# DDR32SS0_CTLPHY_WRAP_CTL_CFG_CTLCFG register map
Vendor: Texas Instruments
Registers are 32-bit, read-write, reset 0x0 unless marked. A register's access mark holds for its fields unless they carry their own. Offsets are as the file gives them; [hi:lo] are bit positions; lines under a group give offsets from that group; {n}, {i} and the like mark numbered series.

## DDR32SS0_CTLPHY_WRAP_CTL_CFG_CTLCFG (part 4 of 11)
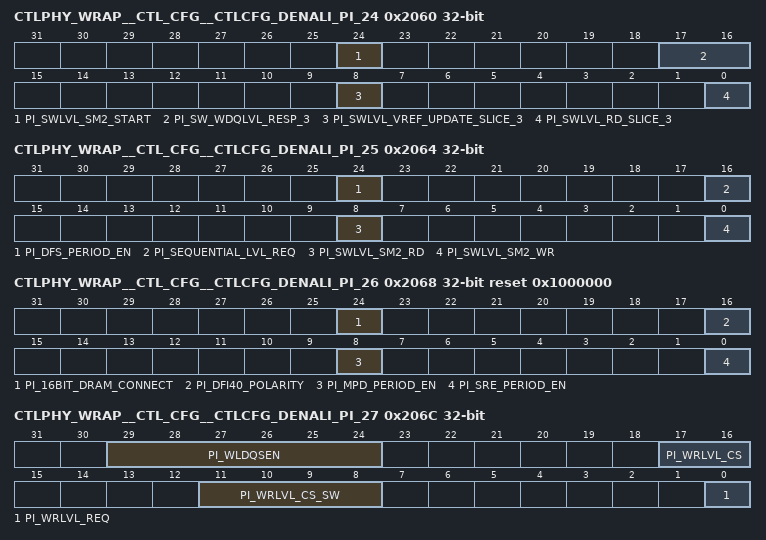
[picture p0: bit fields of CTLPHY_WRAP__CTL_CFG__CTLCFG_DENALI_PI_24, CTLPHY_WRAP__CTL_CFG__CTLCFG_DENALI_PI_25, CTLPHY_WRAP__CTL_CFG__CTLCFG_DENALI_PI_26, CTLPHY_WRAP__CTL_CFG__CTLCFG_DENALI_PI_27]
0x2060 CTLPHY_WRAP__CTL_CFG__CTLCFG_DENALI_PI_24 access per field
  [24] PI_SWLVL_SM2_START wo — SW leveling start command for stage 2. WRITE-ONLY
  [17:16] PI_SW_WDQLVL_RESP_3 ro — Leveling response for data slice 3. READ-ONLY
  [8] PI_SWLVL_VREF_UPDATE_SLICE_3 wo — SW leveling vref update command in WDQ training. WRITE-ONLY
  [0] PI_SWLVL_RD_SLICE_3 wo — SW leveling read command in WDQ training. WRITE-ONLY
0x2064 CTLPHY_WRAP__CTL_CFG__CTLCFG_DENALI_PI_25 access per field
  [24] PI_DFS_PERIOD_EN rw — Enable the DFS triggered periodic leveling.
  [16] PI_SEQUENTIAL_LVL_REQ wo — User request to initiate all possible leveling sequences. Set to 1 to trigger. WRITE-ONLY
  [8] PI_SWLVL_SM2_RD wo — SW leveling read command for stage 2. WRITE-ONLY
  [0] PI_SWLVL_SM2_WR wo — SW leveling write command for stage 2. WRITE-ONLY
0x2068 CTLPHY_WRAP__CTL_CFG__CTLCFG_DENALI_PI_26 reset 0x1000000
  [24] PI_16BIT_DRAM_CONNECT — Enable 16/32 bit DRAM configuration. 0: 16bit DRAM. 1: 32 bit DRAM.
  [16] PI_DFI40_POLARITY — Defines the polarity of the dfi_wrdata_cs_n/dfi_rddata_cs_n signals.
  [8] PI_MPD_PERIOD_EN — Enable the max power saving mode exit triggered periodic leveling.
  [0] PI_SRE_PERIOD_EN — Enable the self refresh exit triggered periodic leveling.
0x206C CTLPHY_WRAP__CTL_CFG__CTLCFG_DENALI_PI_27 access per field
  [29:24] PI_WLDQSEN rw — Delay from issuing MRS to first DQS strobe for write leveling.
  [17:16] PI_WRLVL_CS rw — Specifies the target chip select for the write leveling operation initiated through the WRLVL_REQ parameter.
  [11:8] PI_WRLVL_CS_SW rw — Specifies the target chip select for the write leveling operation initiated through the WRLVL_REQ parameter.
  [0] PI_WRLVL_REQ wo — User request to initiate write leveling. Set to 1 to trigger. WRITE-ONLY
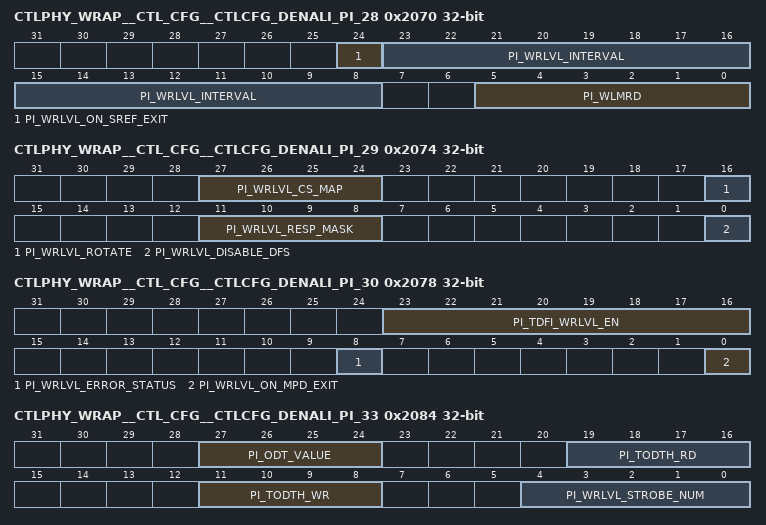
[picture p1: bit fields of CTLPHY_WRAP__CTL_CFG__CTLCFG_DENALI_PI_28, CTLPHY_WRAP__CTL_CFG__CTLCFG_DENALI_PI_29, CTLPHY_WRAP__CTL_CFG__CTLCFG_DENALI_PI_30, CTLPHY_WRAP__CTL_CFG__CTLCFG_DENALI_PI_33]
0x2070 CTLPHY_WRAP__CTL_CFG__CTLCFG_DENALI_PI_28
  [24] PI_WRLVL_ON_SREF_EXIT — Enables automatic write leveling on a self-refresh exit. Set to 1 to enable.
  [23:8] PI_WRLVL_INTERVAL — Number of long count sequences counted between automatic write leveling commands.
  [5:0] PI_WLMRD — Delay from issuing MRS to first write leveling strobe.
0x2074 CTLPHY_WRAP__CTL_CFG__CTLCFG_DENALI_PI_29
  [27:24] PI_WRLVL_CS_MAP — Defines the chip select map for write leveling operations. Bit [0] controls cs0, bit [1] controls cs1, etc. Set each bit to 1 to enable chip for write leveling.
  [16] PI_WRLVL_ROTATE — Enables rotational CS for counter triggered automatic write leveling. Set to 1, only one rank's write levling will process, the rank number is rotational for each time that write leveling been triggered by counter expiring. Set to 0 or not a short pattern leveling [indicated by dfi_lvl_periodic], the counter expired write leveling will process all the ranks.
  [11:8] PI_WRLVL_RESP_MASK — Mask for the dfi_wrlvl_resp signal during write leveling.
  [0] PI_WRLVL_DISABLE_DFS — Disable automatic write leveling on freq change. Set to 1 to disable wrlvl on dfs,set 0 enable wrlvl on dfs.
0x2078 CTLPHY_WRAP__CTL_CFG__CTLCFG_DENALI_PI_30 access per field
  [23:16] PI_TDFI_WRLVL_EN rw — Defines the DFI tWRLVL_EN timing parameter [in DFI clocks], the minimum cycles from a dfi_wrlvl_en assertion to the first dfi_wrlvl_strobe assertion.
  [8] PI_WRLVL_ERROR_STATUS ro — Holds the error associated with the write level error interrupt. Bit [0] set indicates a TDFI_WRLVL_MAX parameter violation and bit [1] set indicates a TDFI_WRLVL_RESP parameter violation. READ-ONLY
  [0] PI_WRLVL_ON_MPD_EXIT rw — Enables automatic write leveling on a maximum power down mode exit. Set to 1 to enable.
0x207C CTLPHY_WRAP__CTL_CFG__CTLCFG_DENALI_PI_31
  [31:0] PI_TDFI_WRLVL_RESP — Defines the DFI tWRLVL_RESP timing parameter [in DFI clocks], the maximum cycles between a dfi_wrlvl_req assertion and a dfi_wrlvl_en assertion.
0x2080 CTLPHY_WRAP__CTL_CFG__CTLCFG_DENALI_PI_32
  [31:0] PI_TDFI_WRLVL_MAX — Defines the DFI tWRLVL_MAX timing parameter [in DFI clocks], the maximum cycles between a dfi_wrlvl_en assertion and a valid dfi_wrlvl_resp.
0x2084 CTLPHY_WRAP__CTL_CFG__CTLCFG_DENALI_PI_33
  [27:24] PI_ODT_VALUE — When using LPDDR4, this value will be driven out on the dfi_odt signal.
  [19:16] PI_TODTH_RD — Defines the minimum DRAM cycles of ODT high time for a read command, in memory clocks.
  [11:8] PI_TODTH_WR — Defines the minimum DRAM cycles of ODT high time for a write command, in memory clocks.
  [4:0] PI_WRLVL_STROBE_NUM — Defines the number of write leveling strobes generated.
0x2088 CTLPHY_WRAP__CTL_CFG__CTLCFG_DENALI_PI_34
  [3:0] PI_ADDRESS_MIRRORING — Indicates which chip selects support address mirroring. Bit [0] controls cs0, bit [1] controls cs1, etc. Set each bit to 1 to enable.
0x208C CTLPHY_WRAP__CTL_CFG__CTLCFG_DENALI_PI_35
  [25:0] PI_CA_PARITY_ERROR_INJECT — Selects bit to corrupt on the CA bus for CA parity error injection.
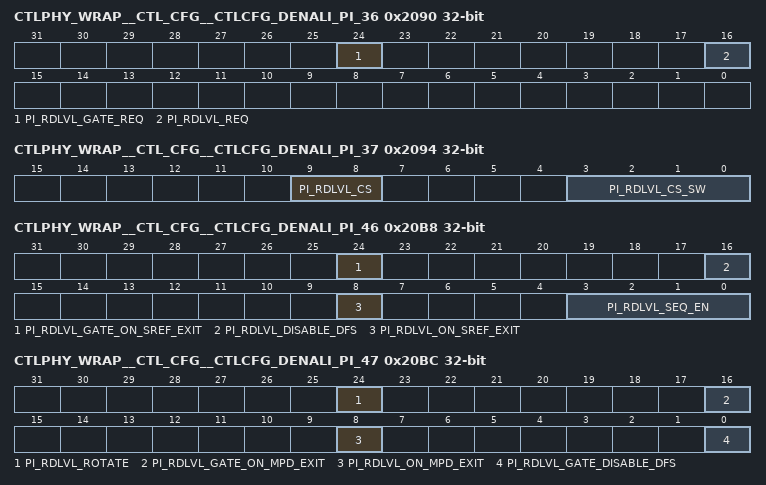
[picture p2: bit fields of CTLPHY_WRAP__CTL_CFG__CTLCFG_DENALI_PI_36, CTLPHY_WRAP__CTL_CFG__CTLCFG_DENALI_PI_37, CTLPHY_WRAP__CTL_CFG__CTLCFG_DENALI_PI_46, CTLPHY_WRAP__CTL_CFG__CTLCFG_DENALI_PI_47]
0x2090 CTLPHY_WRAP__CTL_CFG__CTLCFG_DENALI_PI_36 wo
  [24] PI_RDLVL_GATE_REQ — User request to initiate gate training. Set to 1 to trigger. WRITE-ONLY
  [16] PI_RDLVL_REQ — User request to initiate data eye training. Set to 1 to trigger. WRITE-ONLY
0x2094 CTLPHY_WRAP__CTL_CFG__CTLCFG_DENALI_PI_37
  [9:8] PI_RDLVL_CS — Specifies the target chip select for the data eye training operation initiated through the RDLVL_REQ parameter or the gate training operation initiated through the RDLVL_GATE_REQ parameter.
  [3:0] PI_RDLVL_CS_SW — Specifies the target chip select for the data eye training operation initiated through the RDLVL_REQ parameter or the gate training operation initiated through the RDLVL_GATE_REQ parameter.
{0x2000+4i} CTLPHY_WRAP__CTL_CFG__CTLCFG_DENALI_PI_{i} (i=38..45)
  [31:0] PI_RDLVL_PAT_{i-38} — Non-default pattern {i-38} used for read data eye training of DDR4 or LPDDR4, and read dbi training of DDR4.
0x20B8 CTLPHY_WRAP__CTL_CFG__CTLCFG_DENALI_PI_46
  [24] PI_RDLVL_GATE_ON_SREF_EXIT — Enables automatic gate training on a self-refresh exit. Set to 1 to enable.
  [16] PI_RDLVL_DISABLE_DFS — Disables automatic data eye training on freq change. Set to 1 to disable rdlvl on dfs,Set to 0 to enable rdlvl on dfs.
  [8] PI_RDLVL_ON_SREF_EXIT — Enables automatic data eye training on a self-refresh exit. Set to 1 to enable.
  [3:0] PI_RDLVL_SEQ_EN — Specifies the pattern, format and MPR for data eye training.
0x20BC CTLPHY_WRAP__CTL_CFG__CTLCFG_DENALI_PI_47
  [24] PI_RDLVL_ROTATE — Enables rotational CS for interval data eye training. Set to 1 for rotating CS.
  [16] PI_RDLVL_GATE_ON_MPD_EXIT — Enables automatic gate training on a maximum power down mode exit. Set to 1 to enable.
  [8] PI_RDLVL_ON_MPD_EXIT — Enables automatic data eye training on a maximum power down mode exit. Set to 1 to enable.
  [0] PI_RDLVL_GATE_DISABLE_DFS — Disables automatic gate training on freq change. Set to 1 to disable rdlvl_gate on dfs,Set to 0 to enable rdlvl_gate on dfs.
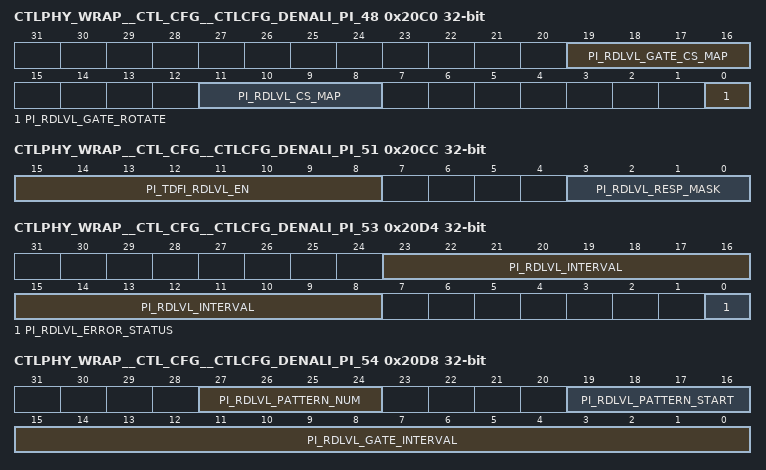
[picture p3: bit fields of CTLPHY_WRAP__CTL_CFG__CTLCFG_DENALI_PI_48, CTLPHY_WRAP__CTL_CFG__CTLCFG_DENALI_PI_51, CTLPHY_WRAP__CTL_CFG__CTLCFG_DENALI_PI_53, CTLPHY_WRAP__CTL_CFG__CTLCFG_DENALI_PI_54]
0x20C0 CTLPHY_WRAP__CTL_CFG__CTLCFG_DENALI_PI_48
  [19:16] PI_RDLVL_GATE_CS_MAP — Defines the chip select map for gate training operations. Bit [0] controls cs0, bit [1] controls cs1, etc. Set each bit to 1 to enable chip for gate training.
  [11:8] PI_RDLVL_CS_MAP — Defines the chip select map for data eye training operations. Bit [0] controls cs0, bit [1] controls cs1, etc. Set each bit to 1 to enable chip for data eye training.
  [0] PI_RDLVL_GATE_ROTATE — Enables rotational CS for interval gate training. Set to 1 for rotating CS.
0x20C4 CTLPHY_WRAP__CTL_CFG__CTLCFG_DENALI_PI_49
  [9:0] PI_TDFI_RDLVL_RR — Defines the DFI tRDLVL_RR timing parameter [in DFI clocks], the minimum cycles between read commands.
0x20C8 CTLPHY_WRAP__CTL_CFG__CTLCFG_DENALI_PI_50
  [31:0] PI_TDFI_RDLVL_RESP — Defines the DFI tRDLVL_RESP timing parameter [in DFI clocks], the maximum cycles between a dfi_rdlvl_req or dfi_rdlvl_gate_req assertion and a dfi_rdlvl_en or dfi_rdlvl_gate_en assertion.
0x20CC CTLPHY_WRAP__CTL_CFG__CTLCFG_DENALI_PI_51
  [15:8] PI_TDFI_RDLVL_EN — Defines the DFI tRDLVL_EN timing parameter [in DFI clocks], the minimum cycles from a dfi_rdlvl_en or dfi_rdlvl_gate_en assertion to the first read or MRR. Set to 1 means the minium value[1 cycle], set to 0 means the maxium value
  [3:0] PI_RDLVL_RESP_MASK — Mask for the dfi_rdlvl_resp signal during data eye training.
0x20D0 CTLPHY_WRAP__CTL_CFG__CTLCFG_DENALI_PI_52
  [31:0] PI_TDFI_RDLVL_MAX — Defines the DFI tRDLVL_MAX timing parameter [in DFI clocks], the maximum cycles between a dfi_rdlvl_en or dfi_rdlvl_gate_en assertion and a valid dfi_rdlvl_resp.
0x20D4 CTLPHY_WRAP__CTL_CFG__CTLCFG_DENALI_PI_53 access per field
  [23:8] PI_RDLVL_INTERVAL rw — Number of long count sequences counted between automatic data eye training commands.
  [0] PI_RDLVL_ERROR_STATUS ro — Holds the error associated with the data eye training error or gate training error interrupt. Uppermost bit set indicates a TDFI_RDLVL_RESP parameter violation. Next uppermost bit set indicates a TDFI_RDLVL_MAX parameter violation. Lower bits are reserved. READ-ONLY
0x20D8 CTLPHY_WRAP__CTL_CFG__CTLCFG_DENALI_PI_54
  [27:24] PI_RDLVL_PATTERN_NUM — Defines the number of pattern supported in read leveling.
  [19:16] PI_RDLVL_PATTERN_START — Defines the start pattern in read leveling.
  [15:0] PI_RDLVL_GATE_INTERVAL — Number of long count sequences counted between automatic gate training commands.
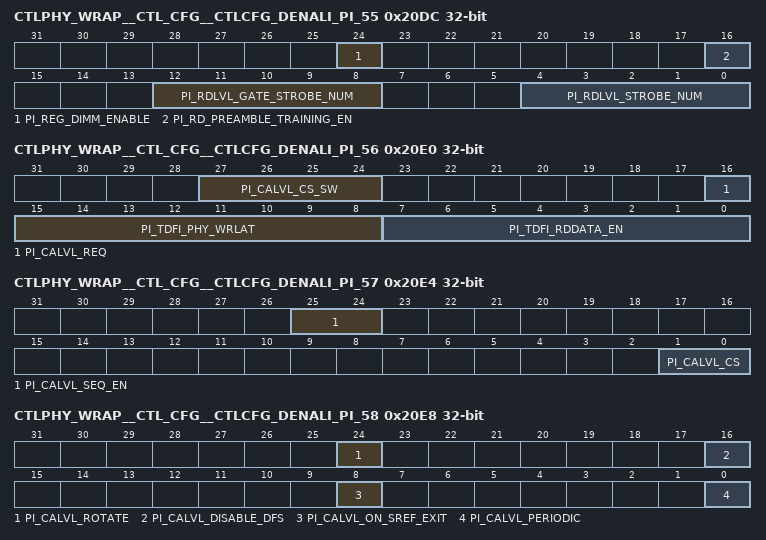
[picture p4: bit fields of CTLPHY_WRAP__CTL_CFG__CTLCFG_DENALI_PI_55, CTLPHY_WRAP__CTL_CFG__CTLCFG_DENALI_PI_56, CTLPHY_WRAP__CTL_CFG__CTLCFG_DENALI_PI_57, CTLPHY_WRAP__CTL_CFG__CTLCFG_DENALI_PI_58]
0x20DC CTLPHY_WRAP__CTL_CFG__CTLCFG_DENALI_PI_55
  [24] PI_REG_DIMM_ENABLE — Enable registered DIMM operation. Set to 1 to enable.
  [16] PI_RD_PREAMBLE_TRAINING_EN — Enable read preamble training during gate training. Set to 1 to enable.
  [12:8] PI_RDLVL_GATE_STROBE_NUM — Defines the number of back to back MPC command in one read process in read gate training.
  [4:0] PI_RDLVL_STROBE_NUM — Defines the number of back to back MPC command in one read process in read eye training.
0x20E0 CTLPHY_WRAP__CTL_CFG__CTLCFG_DENALI_PI_56 access per field
  [27:24] PI_CALVL_CS_SW rw — Specifies the target chip select for the CA training operation initiated through the CALVL_REQ parameter.
  [16] PI_CALVL_REQ wo — User request to initiate CA training. Set to 1 to trigger. WRITE-ONLY
  [15:8] PI_TDFI_PHY_WRLAT ro — Holds the calculated DFI tPHY_WRLAT timing parameter [in DFI PHY clocks], the maximum cycles between a write command and a dfi_wrdata_en assertion. READ-ONLY
  [7:0] PI_TDFI_RDDATA_EN ro — Holds the calculated DFI tRDDATA_EN timing parameter [in DFI PHY clocks], the maximum cycles between a read command and a dfi_rddata_en assertion. READ-ONLY
0x20E4 CTLPHY_WRAP__CTL_CFG__CTLCFG_DENALI_PI_57
  [25:24] PI_CALVL_SEQ_EN — Specifies which CA training patterns will be used. Set to 0 for pattern 0 only, set to 1 for patterns 0 and 1, set to 2 for patterns 0, 1 and 2, or set to 3 for all patterns.
  [1:0] PI_CALVL_CS — Specifies the target chip select for the CA training operation initiated through the CALVL_REQ parameter.
0x20E8 CTLPHY_WRAP__CTL_CFG__CTLCFG_DENALI_PI_58
  [24] PI_CALVL_ROTATE — Enables rotational CS for interval CA training. Set to 1 for rotating CS.
  [16] PI_CALVL_DISABLE_DFS — Disables automatic CA training on freq change. Set to 1 to disable CA training on dfs, Set to 0 to enable CA training .
  [8] PI_CALVL_ON_SREF_EXIT — Enables automatic CA training on a self-refresh exit. Set to 1 to enable.
  [0] PI_CALVL_PERIODIC — Enables the use of the dfi_lvl_periodic signal during CA training. Set to 1 to enable.
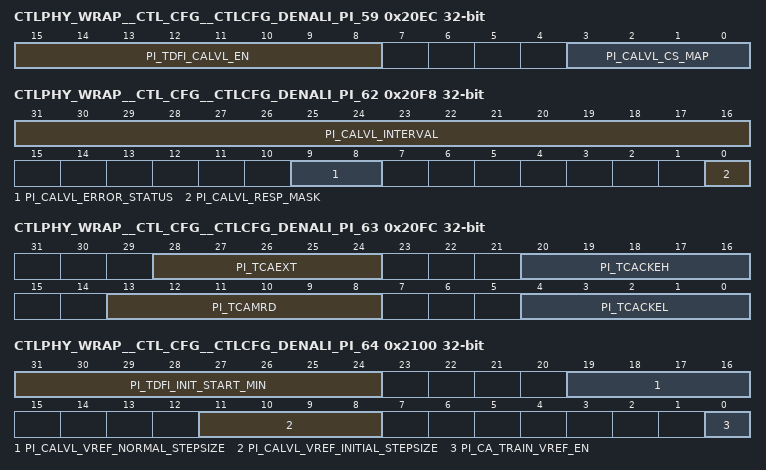
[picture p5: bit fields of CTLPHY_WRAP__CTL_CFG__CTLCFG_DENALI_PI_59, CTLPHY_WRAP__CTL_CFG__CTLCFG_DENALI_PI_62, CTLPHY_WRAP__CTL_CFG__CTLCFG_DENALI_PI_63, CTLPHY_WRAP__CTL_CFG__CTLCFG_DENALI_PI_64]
0x20EC CTLPHY_WRAP__CTL_CFG__CTLCFG_DENALI_PI_59
  [15:8] PI_TDFI_CALVL_EN — Defines the DFI tCALVL_EN timing parameter [in DFI clocks], the minimum cycles between a dfi_calvl_en assertion and a dfi_cke de-assertion.
  [3:0] PI_CALVL_CS_MAP — Defines the chip select map for CA training operations. Bit [0] controls cs0, bit [1] controls cs1, etc. Set each bit to 1 to enable chip for CA training.
0x20F0 CTLPHY_WRAP__CTL_CFG__CTLCFG_DENALI_PI_60
  [31:0] PI_TDFI_CALVL_RESP — Defines the DFI tCALVL_RESP timing parameter [in DFI clocks], the maximum cycles between a dfi_calvl_req assertion and a dfi_calvl_en assertion.
0x20F4 CTLPHY_WRAP__CTL_CFG__CTLCFG_DENALI_PI_61
  [31:0] PI_TDFI_CALVL_MAX — Defines the DFI tCALVL_MAX timing parameter [in DFI clocks], the maximum cycles between a dfi_calvl_en assertion and a valid dfi_calvl_resp.
0x20F8 CTLPHY_WRAP__CTL_CFG__CTLCFG_DENALI_PI_62 access per field
  [31:16] PI_CALVL_INTERVAL rw — Number of long count sequences counted between automatic CA training commands.
  [9:8] PI_CALVL_ERROR_STATUS ro — Holds the error associated with the CA training error interrupt. Bit [0] set indicates a TDFI_CALVL_RESP parameter violation and bit [1] set indicates a TDFI_CALVL_MAX parameter violation. READ-ONLY
  [0] PI_CALVL_RESP_MASK rw — Mask for the dfi_calvl_resp signal during CA training.
0x20FC CTLPHY_WRAP__CTL_CFG__CTLCFG_DENALI_PI_63
  [28:24] PI_TCAEXT — DRAM tCAEXT value in memory cycles.
  [20:16] PI_TCACKEH — DRAM tCACKEH value in memory cycles.
  [13:8] PI_TCAMRD — DRAM tCAMRD value in memory cycles.
  [4:0] PI_TCACKEL — DRAM tCACKEL value in memory cycles.
0x2100 CTLPHY_WRAP__CTL_CFG__CTLCFG_DENALI_PI_64
  [31:24] PI_TDFI_INIT_START_MIN — Minimum number of DFI clocks before dfi_init_start can be driven after a previous command/training event.
  [19:16] PI_CALVL_VREF_NORMAL_STEPSIZE — The adjust step for the post-initial Vref[ca] training.
  [11:8] PI_CALVL_VREF_INITIAL_STEPSIZE — The adjust step for the initial Vref[ca] training.
  [0] PI_CA_TRAIN_VREF_EN — Control for VREF training during CA training post power-on initialization. Set to enable VREF training.
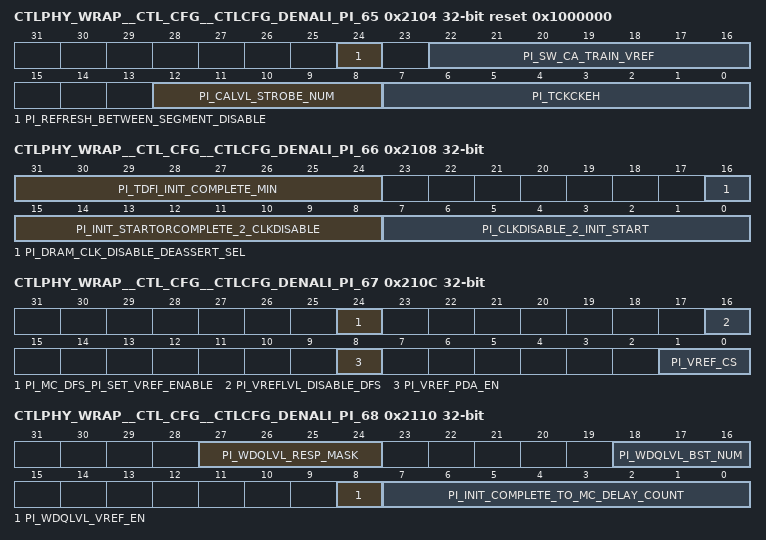
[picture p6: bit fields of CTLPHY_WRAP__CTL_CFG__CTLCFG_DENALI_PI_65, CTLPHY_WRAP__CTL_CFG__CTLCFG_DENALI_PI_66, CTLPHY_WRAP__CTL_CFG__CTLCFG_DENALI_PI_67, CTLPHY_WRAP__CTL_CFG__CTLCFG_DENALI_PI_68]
0x2104 CTLPHY_WRAP__CTL_CFG__CTLCFG_DENALI_PI_65 reset 0x1000000
  [24] PI_REFRESH_BETWEEN_SEGMENT_DISABLE — Disable the refresh between CA first and second segment training. Set to 1 to disable.
  [22:16] PI_SW_CA_TRAIN_VREF — The Vref value which is set for SW step by step CA training.
  [12:8] PI_CALVL_STROBE_NUM — The consecutive dfi_calvl_strobe number when updating the CA vref data.
  [7:0] PI_TCKCKEH — DRAM tCKELCK Clock and command valid before CKE HIGH.
0x2108 CTLPHY_WRAP__CTL_CFG__CTLCFG_DENALI_PI_66
  [31:24] PI_TDFI_INIT_COMPLETE_MIN — Minimum number of DFI clocks from dfi_init_complete to a command/training event.
  [16] PI_DRAM_CLK_DISABLE_DEASSERT_SEL — Indicate dfi_dram_clk_disable deassert following dfi_init_start deassert or dfi_init_complete assert. Set to 0: dfi_dram_clk_disable deassert following dfi_init_start deassert. Set to 1: dfi_dram_clk_disable deassert following dfi_init_complete assert.
  [15:8] PI_INIT_STARTORCOMPLETE_2_CLKDISABLE — Defines the delay from deasserting of dfi_init_start or asserting of dfi_init_complete to deasserting of dfi_dram_clk_disable in DFI clock.
  [7:0] PI_CLKDISABLE_2_INIT_START — Defines the delay from the asserting of dfi_dram_clk_disable to the asserting of dfi_init_start in DFI clock.
0x210C CTLPHY_WRAP__CTL_CFG__CTLCFG_DENALI_PI_67
  [24] PI_MC_DFS_PI_SET_VREF_ENABLE — Enable the PI to set VREF value after DFS issued by MC. MR12 and MR14 for LPDDR4. MR6 for DDR4. 1 means disable.
  [16] PI_VREFLVL_DISABLE_DFS — Disables automatic VREF training on freq change. Set to 1 to disable.
  [8] PI_VREF_PDA_EN — Enable per-DRAM addressability during VREF training. Set to 1 to enable.
  [1:0] PI_VREF_CS — Specifies the target chip select for the VREF training operation.
0x2110 CTLPHY_WRAP__CTL_CFG__CTLCFG_DENALI_PI_68
  [27:24] PI_WDQLVL_RESP_MASK — Write DQ training response mask. When set to 1, the dfi_wdqlvl_en of the slice is not asserted.
  [18:16] PI_WDQLVL_BST_NUM — Defines the number of write/read bursts issued at each step in write DQ training.
  [8] PI_WDQLVL_VREF_EN — Control for VREF training as part of non-initialization write DQ training.
  [7:0] PI_INIT_COMPLETE_TO_MC_DELAY_COUNT — It controls the time PI bypass CKE at the beginning of PI mask dfi_init_complete to controller.
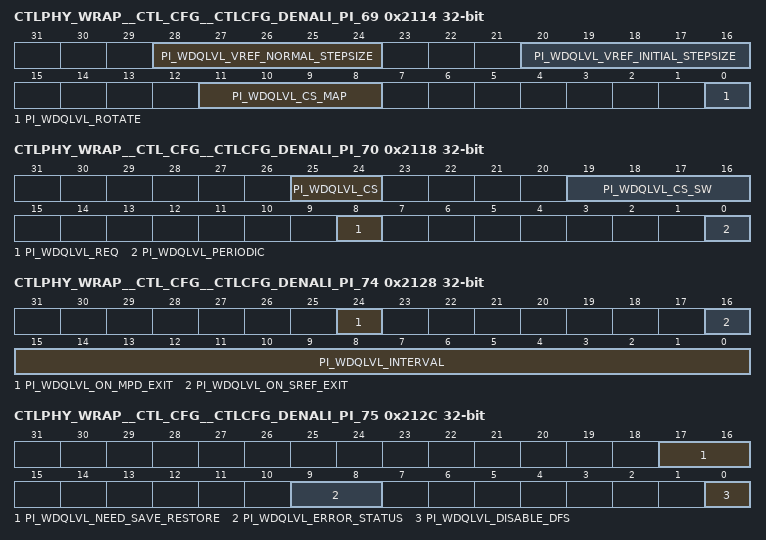
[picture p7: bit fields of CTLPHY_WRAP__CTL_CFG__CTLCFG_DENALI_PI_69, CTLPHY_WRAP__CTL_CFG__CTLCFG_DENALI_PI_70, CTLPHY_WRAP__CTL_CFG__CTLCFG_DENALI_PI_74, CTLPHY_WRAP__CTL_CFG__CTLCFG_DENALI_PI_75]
0x2114 CTLPHY_WRAP__CTL_CFG__CTLCFG_DENALI_PI_69
  [28:24] PI_WDQLVL_VREF_NORMAL_STEPSIZE — Write DQ training vref step size for post_initial training.
  [20:16] PI_WDQLVL_VREF_INITIAL_STEPSIZE — Write DQ training vref step size for initial training.
  [11:8] PI_WDQLVL_CS_MAP — Map of CS's included in write DQ training sequence.
  [0] PI_WDQLVL_ROTATE — Enables write DQ training rotate for interval training.
0x2118 CTLPHY_WRAP__CTL_CFG__CTLCFG_DENALI_PI_70 access per field
  [25:24] PI_WDQLVL_CS rw — Write DQ training target chip select.
  [19:16] PI_WDQLVL_CS_SW rw — Write DQ training target chip select.
  [8] PI_WDQLVL_REQ wo — SW write to initiate Write DQ training request. WRITE-ONLY
  [0] PI_WDQLVL_PERIODIC rw — Enables periodic write DQ training.
0x211C CTLPHY_WRAP__CTL_CFG__CTLCFG_DENALI_PI_71
  [7:0] PI_TDFI_WDQLVL_EN — DFI timing param tWDQLVL_EN. Minimum number of DFI clocks required after the write DQ training enable signal is asserted until the first write command may be asserted.
0x2120 CTLPHY_WRAP__CTL_CFG__CTLCFG_DENALI_PI_72
  [31:0] PI_TDFI_WDQLVL_RESP — DFI timing param tWDQLVL_RESP. Maximum number of DFI clocks that may occur between a write DQ training request and the associated mode enable.
0x2124 CTLPHY_WRAP__CTL_CFG__CTLCFG_DENALI_PI_73
  [31:0] PI_TDFI_WDQLVL_MAX — DFI timing param tWDQLVL_MAX. Maximum number of DFI clocks that the PI will wait for a response from the PHY.
0x2128 CTLPHY_WRAP__CTL_CFG__CTLCFG_DENALI_PI_74
  [24] PI_WDQLVL_ON_MPD_EXIT — Issue a write DQ training command on maximum power saving mode exit.
  [16] PI_WDQLVL_ON_SREF_EXIT — Issue a write DQ training command on self-refresh exit.
  [15:0] PI_WDQLVL_INTERVAL — Sets the maximum number of long count sequences allowed between automatic write DQ training operations.
0x212C CTLPHY_WRAP__CTL_CFG__CTLCFG_DENALI_PI_75 access per field
  [17:16] PI_WDQLVL_NEED_SAVE_RESTORE rw — Enables the use of functional DRAM address space for write DQ training, 1 = enable, not for LPDDR4.
  [9:8] PI_WDQLVL_ERROR_STATUS ro — Holds the error associated with the write dq level error interrupt. Bit [0] set indicates a PI_TDFI_WDQLVL_MAX parameter violation and bit [1] set indicates a PI_TDFI_WDQLVL_RESP parameter violation. READ-ONLY.
  [0] PI_WDQLVL_DISABLE_DFS rw — Disable automatic write DQ training on freq change. Set to 1 to disable.
0x2130 CTLPHY_WRAP__CTL_CFG__CTLCFG_DENALI_PI_76
  [31:0] PI_WDQLVL_DRAM_LVL_START_ADDR_0 — Start address of WDQ leveling, not for LPDDR4.
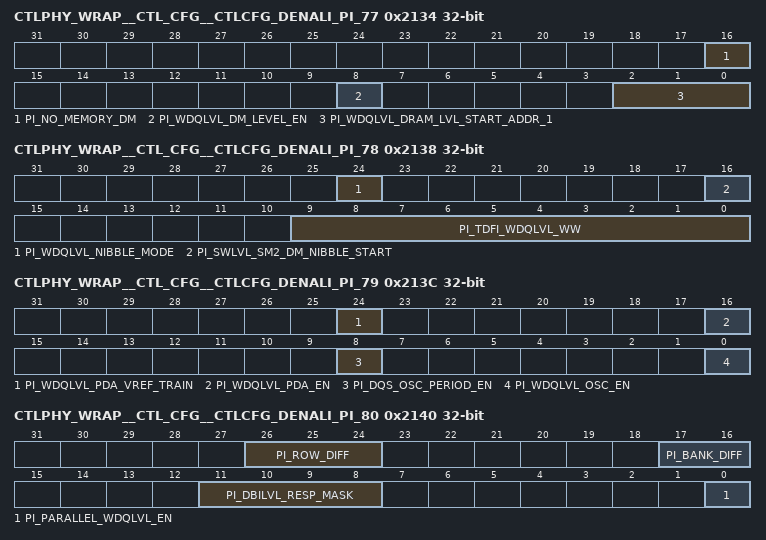
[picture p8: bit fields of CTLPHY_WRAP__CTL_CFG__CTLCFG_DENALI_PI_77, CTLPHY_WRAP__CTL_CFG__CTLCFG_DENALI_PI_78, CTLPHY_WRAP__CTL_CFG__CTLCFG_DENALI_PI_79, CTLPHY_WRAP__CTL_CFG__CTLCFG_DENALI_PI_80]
0x2134 CTLPHY_WRAP__CTL_CFG__CTLCFG_DENALI_PI_77
  [16] PI_NO_MEMORY_DM — Defines if the attached memory supports the Data Mask function, 1 = not supported.
  [8] PI_WDQLVL_DM_LEVEL_EN — Enable for write DM training as part of the write DQ training, not for LPDDR4.
  [2:0] PI_WDQLVL_DRAM_LVL_START_ADDR_1 — Start address of WDQ leveling, not for LPDDR4.
0x2138 CTLPHY_WRAP__CTL_CFG__CTLCFG_DENALI_PI_78 access per field
  [24] PI_WDQLVL_NIBBLE_MODE rw — WDQ Training Nibble mode indication. When set to 1, nibble mode is enabled, and the training timing is doubled.
  [16] PI_SWLVL_SM2_DM_NIBBLE_START wo — Start command for stage 2, when in the process of DM leveling or nibble mode. WRITE-ONLY
  [9:0] PI_TDFI_WDQLVL_WW rw — Minimum number of DFI clocks to be inserted between write commands during the DM portion of write DQ training.
0x213C CTLPHY_WRAP__CTL_CFG__CTLCFG_DENALI_PI_79
  [24] PI_WDQLVL_PDA_VREF_TRAIN — Enable for the use of PDA to set the VREF during write DQ training, 1 = enabled.
  [16] PI_WDQLVL_PDA_EN — Enable for the use of write DQ training for PDA mode, 1 = enabled.
  [8] PI_DQS_OSC_PERIOD_EN — Enable for DQS oscillator triggered periodic write DQ training, 1 = enabled.
  [0] PI_WDQLVL_OSC_EN — Enable for DQS oscillator triggered write DQ training, 1 = enabled.
0x2140 CTLPHY_WRAP__CTL_CFG__CTLCFG_DENALI_PI_80
  [26:24] PI_ROW_DIFF — Difference between number of address pins available and number being used.
  [17:16] PI_BANK_DIFF — Difference between number of bank pins available and number being used.
  [11:8] PI_DBILVL_RESP_MASK — Mask for the dfi_rdlvl_resp signal during read dbi training.
  [0] PI_PARALLEL_WDQLVL_EN — Enable per rank parallel Write DQ training for LPDDR4, 1 = enabled.
0x2144 CTLPHY_WRAP__CTL_CFG__CTLCFG_DENALI_PI_81
  [4:0] PI_TCCD — DRAM CAS-to-CAS value in cycles.
{0x2000+4i} CTLPHY_WRAP__CTL_CFG__CTLCFG_DENALI_PI_{i} access not given reset not defined (i=82..86)
0x215C CTLPHY_WRAP__CTL_CFG__CTLCFG_DENALI_PI_87 ro
  [29:0] PI_INT_STATUS — Status of interrupt features in the PI. READ-ONLY
0x2160 CTLPHY_WRAP__CTL_CFG__CTLCFG_DENALI_PI_88 wo
  [28:0] PI_INT_ACK — Clear the corresponding interrupt bit of the PI_INT_STATUS parameter. WRITE-ONLY
0x2164 CTLPHY_WRAP__CTL_CFG__CTLCFG_DENALI_PI_89
  [29:0] PI_INT_MASK — Mask for PI_int signals from the PI_INT_STATUS parameter.
{0x2000+4i} CTLPHY_WRAP__CTL_CFG__CTLCFG_DENALI_PI_{i} ro (i=90..93)
  [31:0] PI_BIST_EXP_DATA_{i-90} — Expected data on BIST error. READ-ONLY
{0x2000+4i} CTLPHY_WRAP__CTL_CFG__CTLCFG_DENALI_PI_{i} ro (i=94..97)
  [31:0] PI_BIST_FAIL_DATA_{i-94} — Actual data on BIST error. READ-ONLY
0x2188 CTLPHY_WRAP__CTL_CFG__CTLCFG_DENALI_PI_98 ro
  [31:0] PI_BIST_FAIL_ADDR_0 — The burst aligned address of BIST error. READ-ONLY
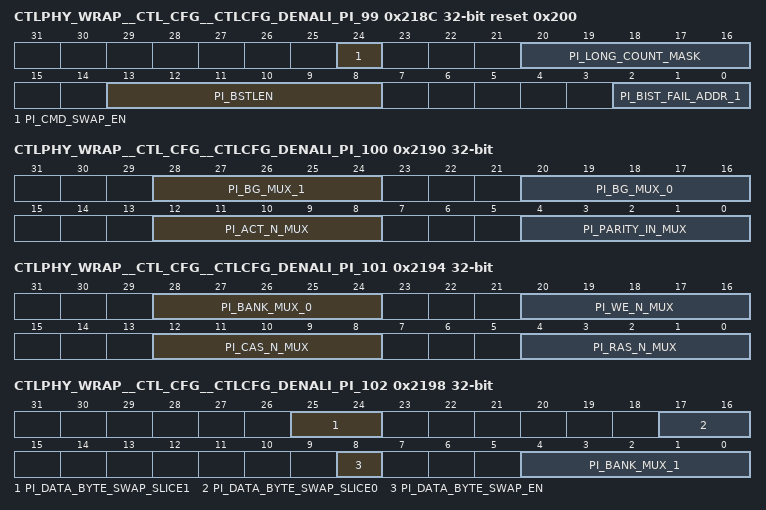
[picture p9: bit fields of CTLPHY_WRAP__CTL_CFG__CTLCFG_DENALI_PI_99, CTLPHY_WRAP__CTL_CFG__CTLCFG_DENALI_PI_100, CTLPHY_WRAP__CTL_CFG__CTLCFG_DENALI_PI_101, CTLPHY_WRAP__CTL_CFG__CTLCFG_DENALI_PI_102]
0x218C CTLPHY_WRAP__CTL_CFG__CTLCFG_DENALI_PI_99 access per field reset 0x200
  [24] PI_CMD_SWAP_EN rw — Command pin swap function enable
  [20:16] PI_LONG_COUNT_MASK rw — Reduces the length of the long counter from 1024 cycles.
  [13:8] PI_BSTLEN rw — Encoded burst length sent to DRAMs during initialization.
  [2:0] PI_BIST_FAIL_ADDR_1 ro — The burst aligned address of BIST error. READ-ONLY
0x2190 CTLPHY_WRAP__CTL_CFG__CTLCFG_DENALI_PI_100
  [28:24] PI_BG_MUX_1 — Command pin BG_1 mux selector
  [20:16] PI_BG_MUX_0 — Command pin BG_0 mux selector
  [12:8] PI_ACT_N_MUX — Command pin ACT_N mux selector
  [4:0] PI_PARITY_IN_MUX — Command pin parity mux selector
0x2194 CTLPHY_WRAP__CTL_CFG__CTLCFG_DENALI_PI_101
  [28:24] PI_BANK_MUX_0 — Command pin BANK_0 mux selector
  [20:16] PI_WE_N_MUX — Command pin WE_N mux selector
  [12:8] PI_CAS_N_MUX — Command pin CAS_N mux selector
  [4:0] PI_RAS_N_MUX — Command pin RAS_N mux selector
0x2198 CTLPHY_WRAP__CTL_CFG__CTLCFG_DENALI_PI_102
  [25:24] PI_DATA_BYTE_SWAP_SLICE1 — DATA pin 1 mux selector
  [17:16] PI_DATA_BYTE_SWAP_SLICE0 — DATA pin 0 mux selector
  [8] PI_DATA_BYTE_SWAP_EN — DATA pin swap function enable
  [4:0] PI_BANK_MUX_1 — Command pin BANK_1 mux selector
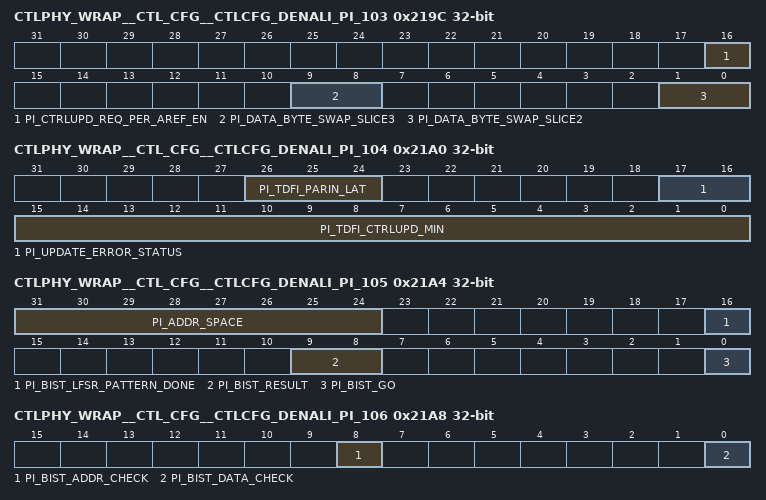
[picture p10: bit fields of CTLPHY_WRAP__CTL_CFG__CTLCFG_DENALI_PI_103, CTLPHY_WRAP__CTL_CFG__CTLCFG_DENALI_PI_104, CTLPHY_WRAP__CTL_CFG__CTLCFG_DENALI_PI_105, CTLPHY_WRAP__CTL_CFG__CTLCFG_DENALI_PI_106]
0x219C CTLPHY_WRAP__CTL_CFG__CTLCFG_DENALI_PI_103
  [16] PI_CTRLUPD_REQ_PER_AREF_EN — Enable an automatic PI initiated update [dfi_ctrlupd_req] after every refresh. Set to 1 to enable.
  [9:8] PI_DATA_BYTE_SWAP_SLICE3 — DATA pin 3 mux selector
  [1:0] PI_DATA_BYTE_SWAP_SLICE2 — DATA pin 2 mux selector
0x21A0 CTLPHY_WRAP__CTL_CFG__CTLCFG_DENALI_PI_104 access per field
  [26:24] PI_TDFI_PARIN_LAT rw — Defines the DFI tPARIN_LAT timing parameter [in DFI PHY clocks], the maximum cycles between a DFI command and a dfi_parity_in signal assertion.
  [17:16] PI_UPDATE_ERROR_STATUS ro — Identifies the source of any DFI PI-initiated update errors. Value of 1 indicates a timing violation of the associated timing parameter. Bit 1-0: ctrlupd_max_error, ctrlupd_interval_error. Bit 6-2: reserved. READ-ONLY
  [15:0] PI_TDFI_CTRLUPD_MIN rw — Reports the DFI tCTRLUPD_MIN timing parameter [in DFI clocks], the minimum cycles that dfi_ctrlupd_req must be asserted.
0x21A4 CTLPHY_WRAP__CTL_CFG__CTLCFG_DENALI_PI_105 access per field
  [31:24] PI_ADDR_SPACE rw — Sets the number of address bits to check during BIST operation. The end address of BIST is start_address+[1 shifted up by PI_ADDR_SPACE]-1. The end address should not beyond the actual memory address range.
  [16] PI_BIST_LFSR_PATTERN_DONE ro — BIST operation lfsr pattern, data pattern 1'b0 means the data is useful,1'b1 means next pattern sequence can ingore. READ-ONLY
  [9:8] PI_BIST_RESULT ro — BIST operation status [pass/fail]. Bit [0] indicates data check status and bit [1] indicates address check status. Value of 1 is a passing result. READ-ONLY
  [0] PI_BIST_GO rw — Initiate a BIST operation. Set to 1 to trigger.
0x21A8 CTLPHY_WRAP__CTL_CFG__CTLCFG_DENALI_PI_106
  [8] PI_BIST_ADDR_CHECK — Enable address checking with BIST operation. Set to 1 to enable.
  [0] PI_BIST_DATA_CHECK — Enable data checking with BIST operation. Set to 1 to enable.
0x21AC CTLPHY_WRAP__CTL_CFG__CTLCFG_DENALI_PI_107
  [31:0] PI_BIST_START_ADDRESS_0 — Start BIST checking at this address.
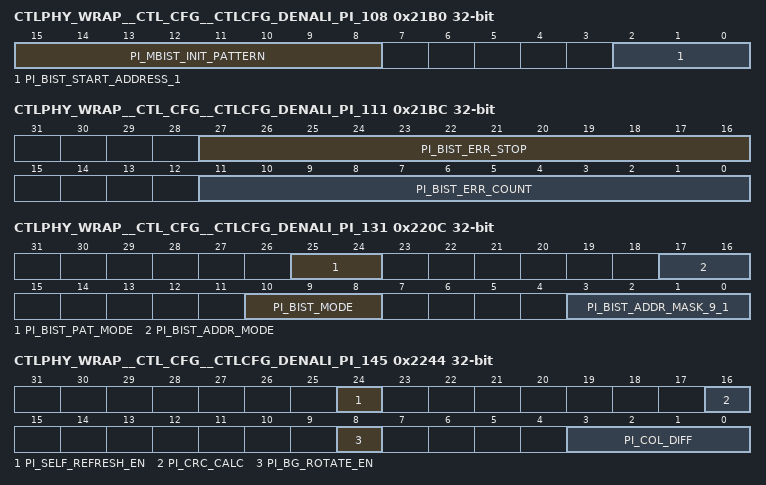
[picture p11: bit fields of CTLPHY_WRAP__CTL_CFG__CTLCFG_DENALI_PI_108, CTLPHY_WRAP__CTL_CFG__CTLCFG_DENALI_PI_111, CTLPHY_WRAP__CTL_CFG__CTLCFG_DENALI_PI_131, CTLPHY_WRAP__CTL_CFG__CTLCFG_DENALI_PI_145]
0x21B0 CTLPHY_WRAP__CTL_CFG__CTLCFG_DENALI_PI_108
  [15:8] PI_MBIST_INIT_PATTERN — PI mbist data check, random lfsr pattern mode init pattern seed.
  [2:0] PI_BIST_START_ADDRESS_1 — Start BIST checking at this address.
0x21B4 CTLPHY_WRAP__CTL_CFG__CTLCFG_DENALI_PI_109
  [31:0] PI_BIST_DATA_MASK_0 — Mask applied to data for BIST error checking. Bit [0] controls memory data path bit [0], bit [1] controls memory data path bit [1], etc. The mask range is the data transfer size in each memory clock cycle [The data on a rising edge and a failing edge]. Set each bit to 1 to mask.
0x21B8 CTLPHY_WRAP__CTL_CFG__CTLCFG_DENALI_PI_110
  [31:0] PI_BIST_DATA_MASK_1 — Mask applied to data for BIST error checking. Bit [0] controls memory data path bit [0], bit [1] controls memory data path bit [1], etc. The mask range is the data transfer size in each memory clock cycle [The data on a rising edge and a failing edge]. Set each bit to 1 to mask.
0x21BC CTLPHY_WRAP__CTL_CFG__CTLCFG_DENALI_PI_111 access per field
  [27:16] PI_BIST_ERR_STOP rw — Defines the maximum number of error occurrences allowed prior to quitting when the BIST_TEST_MODE parameter is set to 1, 2 or 3. A value of 0 will allow the test to run to completion.
  [11:0] PI_BIST_ERR_COUNT ro — Indicates the number of BIST errors found when the BIST_TEST_MODE parameter is set to 1, 2 or 3. READ-ONLY
0x21C0 CTLPHY_WRAP__CTL_CFG__CTLCFG_DENALI_PI_112
  [31:0] PI_BIST_ADDR_MASK_0_0 — Defines an address to be masked during the BIST operation..
0x21C4 CTLPHY_WRAP__CTL_CFG__CTLCFG_DENALI_PI_113
  [3:0] PI_BIST_ADDR_MASK_0_1 — Defines an address to be masked during the BIST operation..
0x21C8 CTLPHY_WRAP__CTL_CFG__CTLCFG_DENALI_PI_114
  [31:0] PI_BIST_ADDR_MASK_1_0 — Defines an address to be masked during the BIST operation..
0x21CC CTLPHY_WRAP__CTL_CFG__CTLCFG_DENALI_PI_115
  [3:0] PI_BIST_ADDR_MASK_1_1 — Defines an address to be masked during the BIST operation..
0x21D0 CTLPHY_WRAP__CTL_CFG__CTLCFG_DENALI_PI_116
  [31:0] PI_BIST_ADDR_MASK_2_0 — Defines an address to be masked during the BIST operation..
0x21D4 CTLPHY_WRAP__CTL_CFG__CTLCFG_DENALI_PI_117
  [3:0] PI_BIST_ADDR_MASK_2_1 — Defines an address to be masked during the BIST operation..
0x21D8 CTLPHY_WRAP__CTL_CFG__CTLCFG_DENALI_PI_118
  [31:0] PI_BIST_ADDR_MASK_3_0 — Defines an address to be masked during the BIST operation..
0x21DC CTLPHY_WRAP__CTL_CFG__CTLCFG_DENALI_PI_119
  [3:0] PI_BIST_ADDR_MASK_3_1 — Defines an address to be masked during the BIST operation..
0x21E0 CTLPHY_WRAP__CTL_CFG__CTLCFG_DENALI_PI_120
  [31:0] PI_BIST_ADDR_MASK_4_0 — Defines an address to be masked during the BIST operation..
0x21E4 CTLPHY_WRAP__CTL_CFG__CTLCFG_DENALI_PI_121
  [3:0] PI_BIST_ADDR_MASK_4_1 — Defines an address to be masked during the BIST operation..
0x21E8 CTLPHY_WRAP__CTL_CFG__CTLCFG_DENALI_PI_122
  [31:0] PI_BIST_ADDR_MASK_5_0 — Defines an address to be masked during the BIST operation..
0x21EC CTLPHY_WRAP__CTL_CFG__CTLCFG_DENALI_PI_123
  [3:0] PI_BIST_ADDR_MASK_5_1 — Defines an address to be masked during the BIST operation..
0x21F0 CTLPHY_WRAP__CTL_CFG__CTLCFG_DENALI_PI_124
  [31:0] PI_BIST_ADDR_MASK_6_0 — Defines an address to be masked during the BIST operation..
0x21F4 CTLPHY_WRAP__CTL_CFG__CTLCFG_DENALI_PI_125
  [3:0] PI_BIST_ADDR_MASK_6_1 — Defines an address to be masked during the BIST operation..
0x21F8 CTLPHY_WRAP__CTL_CFG__CTLCFG_DENALI_PI_126
  [31:0] PI_BIST_ADDR_MASK_7_0 — Defines an address to be masked during the BIST operation..
0x21FC CTLPHY_WRAP__CTL_CFG__CTLCFG_DENALI_PI_127
  [3:0] PI_BIST_ADDR_MASK_7_1 — Defines an address to be masked during the BIST operation..
0x2200 CTLPHY_WRAP__CTL_CFG__CTLCFG_DENALI_PI_128
  [31:0] PI_BIST_ADDR_MASK_8_0 — Defines an address to be masked during the BIST operation..
0x2204 CTLPHY_WRAP__CTL_CFG__CTLCFG_DENALI_PI_129
  [3:0] PI_BIST_ADDR_MASK_8_1 — Defines an address to be masked during the BIST operation..
0x2208 CTLPHY_WRAP__CTL_CFG__CTLCFG_DENALI_PI_130
  [31:0] PI_BIST_ADDR_MASK_9_0 — Defines an address to be masked during the BIST operation..
0x220C CTLPHY_WRAP__CTL_CFG__CTLCFG_DENALI_PI_131
  [25:24] PI_BIST_PAT_MODE — Sets the pattern mode of BIST. 'b00 indicates using built-in pattern. 'b01 indicates checkerboard pattern, each data transfer inverts the last data transfer based on the built-in pattern. 'b10 indicates using both user pattern and built-in pattern. 'b11 indicates using pi lfsr random pattern.
  [17:16] PI_BIST_ADDR_MODE — Sets the address traversing order of BIST. 'b00 indicates fast column order [burst-column-bank-row-rank]. 'b01 indicates fast row order [burst-row-column-bank-rank]. 'b10 indicates fast bank order [burst-bank-column-row-rank].
  [10:8] PI_BIST_MODE — Sets the BIST data checking mode. 'b00 indicates MOVI13N mode. 'b01 indicates March C mode. 'b10 indicates GALPAT mode. 'b11 indicates PRBS mode. 'b100 indicates programmable March data check mode.
  [3:0] PI_BIST_ADDR_MASK_9_1 — Defines an address to be masked during the BIST operation..
{0x2000+4i} CTLPHY_WRAP__CTL_CFG__CTLCFG_DENALI_PI_{i} (i=132..135)
  [31:0] PI_BIST_USER_PAT_{i-132} — Sets the user-specified pattern of BIST.
0x2220 CTLPHY_WRAP__CTL_CFG__CTLCFG_DENALI_PI_136
  [6:0] PI_BIST_PAT_NUM — Sets the max used pattern number of BIST from a total of 8 built-in patterns. Ex. set to 3, The BIST would use pattern 1, 2 and 3.
{0x2000+4i} CTLPHY_WRAP__CTL_CFG__CTLCFG_DENALI_PI_{i} (i=137..144)
  [29:0] PI_BIST_STAGE_{i-137} — Sets the programmable algorithm of each stage X when pi_bist_mmode = 'h4.
0x2244 CTLPHY_WRAP__CTL_CFG__CTLCFG_DENALI_PI_145
  [24] PI_SELF_REFRESH_EN — Control for PI to enable self refresh mode. Set to 1 to enable.
  [16] PI_CRC_CALC — Defines where CRC is performed; set to 1 for PI responsibility or clear to 0 for PHY responsibility.
  [8] PI_BG_ROTATE_EN — Enable bank group rotation. Set to 1 to enable.
  [3:0] PI_COL_DIFF — Difference between number of column pins available and number being used.
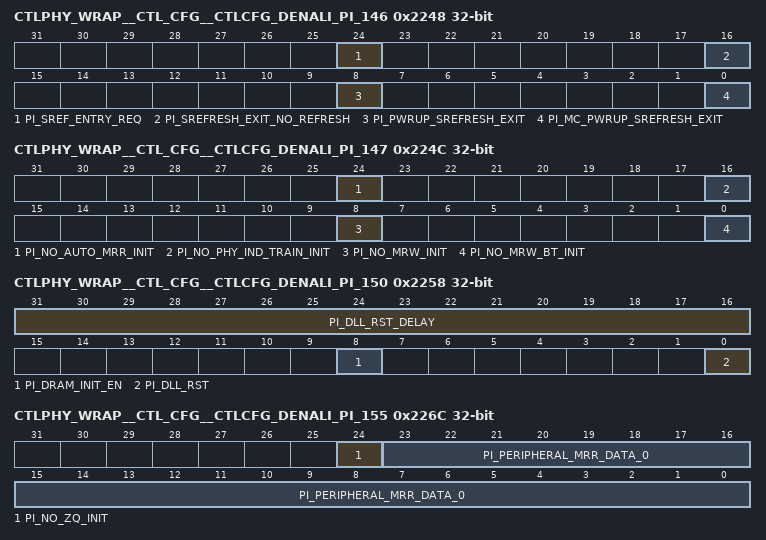
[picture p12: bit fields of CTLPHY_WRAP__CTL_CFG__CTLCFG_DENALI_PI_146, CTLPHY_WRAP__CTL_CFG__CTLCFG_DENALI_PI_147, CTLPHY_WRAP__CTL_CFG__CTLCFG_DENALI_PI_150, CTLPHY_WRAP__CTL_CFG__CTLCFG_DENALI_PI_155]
0x2248 CTLPHY_WRAP__CTL_CFG__CTLCFG_DENALI_PI_146 access per field
  [24] PI_SREF_ENTRY_REQ wo — In PI power up data retention, PI can issued sref entry command. WRITE-ONLY
  [16] PI_SREFRESH_EXIT_NO_REFRESH rw — Disables the automatic refresh request associated with self-refresh exit. Set to 1 to disable.
  [8] PI_PWRUP_SREFRESH_EXIT rw — PI control powerup via self-refresh instead of full memory initialization. Set to 1 to enable.
  [0] PI_MC_PWRUP_SREFRESH_EXIT rw — It indicates MC control powerup via self-refresh instead of full memory initialization. Set to 1 to enable.
0x224C CTLPHY_WRAP__CTL_CFG__CTLCFG_DENALI_PI_147
  [24] PI_NO_AUTO_MRR_INIT — Disable MRR commands during initialization. Set to 1 to disable.
  [16] PI_NO_PHY_IND_TRAIN_INIT — Disable PHY Independent Training during initialization. Set to 1 to disable.
  [8] PI_NO_MRW_INIT — Disable MRW commands after training during initialization. Set to 1 to disable.
  [0] PI_NO_MRW_BT_INIT — Disable MRW commands before training during initialization. Set to 1 to disable.
0x2250 CTLPHY_WRAP__CTL_CFG__CTLCFG_DENALI_PI_148
  [31:0] PI_TRST_PWRON — Duration of memory reset during power-on initialization.
0x2254 CTLPHY_WRAP__CTL_CFG__CTLCFG_DENALI_PI_149
  [31:0] PI_CKE_INACTIVE — Number of cycles after reset before CKE will be active.
0x2258 CTLPHY_WRAP__CTL_CFG__CTLCFG_DENALI_PI_150
  [31:16] PI_DLL_RST_DELAY — Minimum cycles required for DLL reset signal dll_rst_n to be held.
  [8] PI_DRAM_INIT_EN — Control for the initialization of DRAM by the PI.
  [0] PI_DLL_RST — Enables use of the DLL reset [dll_rst_n].
0x225C CTLPHY_WRAP__CTL_CFG__CTLCFG_DENALI_PI_151
  [7:0] PI_DLL_RST_ADJ_DLY — Minimum cycles after setting controller delay in DLL until the DLL reset signal dll_rst_n may be asserted.
0x2260 CTLPHY_WRAP__CTL_CFG__CTLCFG_DENALI_PI_152
  [25:0] PI_WRITE_MODEREG — Write memory mode register data to the DRAMs. Bits [7:0] define the memory mode register number if bit [23] is set, bits [15:8] define the chip select if bit [24] is clear, bits [23:16] define which memory mode register/s to write, bit [24] defines whether all chip selects will be written, and bit [25] triggers the write.
0x2264 CTLPHY_WRAP__CTL_CFG__CTLCFG_DENALI_PI_153 ro
  [7:0] PI_MRW_STATUS — Write memory mode register status. Bit [0] set indicates a WRITE_MODEREG parameter programming error. Bit [1] set indicates a PASR error. Bit [2] is Reserved. Bit [3] set indicates a self refresh or deep power down error. Bit [4] set indicates that a write to MR3 or MR11 was attempted [write_modereg bit [25] was asserted with bit [17] set, or bit [23] was asserted with bits [7:0] defining MR3 or MR11] during tZQCAL after a ZQ calibration start command. READ-ONLY
0x2268 CTLPHY_WRAP__CTL_CFG__CTLCFG_DENALI_PI_154
  [16:0] PI_READ_MODEREG — Read the specified memory mode register from specified chip when start bit set. Bits [7:0] define the memory mode register and bits [15:8] define the chip select. Set bit [16] to 1 to trigger.
0x226C CTLPHY_WRAP__CTL_CFG__CTLCFG_DENALI_PI_155 access per field
  [24] PI_NO_ZQ_INIT rw — Disable ZQ operations during initialization. Set to 1 to disable.
  [23:0] PI_PERIPHERAL_MRR_DATA_0 ro — Data and chip returned from memory mode register read requested by the READ_MODEREG parameter, Bits [15:0] define MRR data, [23:16] define the chip select. READ-ONLY
0x2270 CTLPHY_WRAP__CTL_CFG__CTLCFG_DENALI_PI_156 ro
  [16] PI_ZQ_REQ_PENDING — Indicates that a ZQ command is currently in progress or waiting to run. When this is asserted, no writes to ZQ_REQ should occur. READ-ONLY
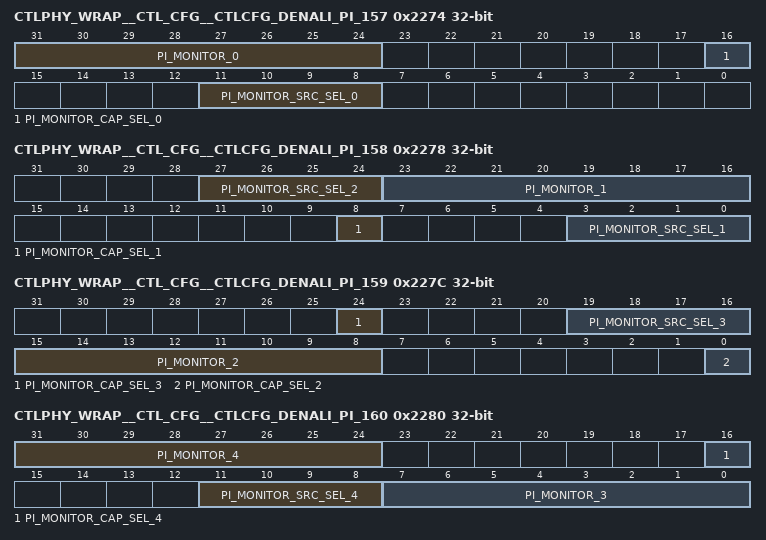
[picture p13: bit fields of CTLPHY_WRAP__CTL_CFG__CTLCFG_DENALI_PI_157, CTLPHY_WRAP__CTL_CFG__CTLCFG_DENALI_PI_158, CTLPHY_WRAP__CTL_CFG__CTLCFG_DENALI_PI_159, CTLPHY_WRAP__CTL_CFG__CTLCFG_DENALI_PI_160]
0x2274 CTLPHY_WRAP__CTL_CFG__CTLCFG_DENALI_PI_157 access per field
  [31:24] PI_MONITOR_0 ro — Monitor register 0. READ-ONLY.
  [16] PI_MONITOR_CAP_SEL_0 rw — Selection of captures for pi_monitor_0.
  [11:8] PI_MONITOR_SRC_SEL_0 rw — Selection of sources for pi_monitor_0.
0x2278 CTLPHY_WRAP__CTL_CFG__CTLCFG_DENALI_PI_158 access per field
  [27:24] PI_MONITOR_SRC_SEL_2 rw — Selection of sources for pi_monitor_2.
  [23:16] PI_MONITOR_1 ro — Monitor register 1. READ-ONLY.
  [8] PI_MONITOR_CAP_SEL_1 rw — Selection of captures for pi_monitor_1.
  [3:0] PI_MONITOR_SRC_SEL_1 rw — Selection of sources for pi_monitor_1.
0x227C CTLPHY_WRAP__CTL_CFG__CTLCFG_DENALI_PI_159 access per field
  [24] PI_MONITOR_CAP_SEL_3 rw — Selection of captures for pi_monitor_3.
  [19:16] PI_MONITOR_SRC_SEL_3 rw — Selection of sources for pi_monitor_3.
  [15:8] PI_MONITOR_2 ro — Monitor register 2. READ-ONLY.
  [0] PI_MONITOR_CAP_SEL_2 rw — Selection of captures for pi_monitor_2.
0x2280 CTLPHY_WRAP__CTL_CFG__CTLCFG_DENALI_PI_160 access per field
  [31:24] PI_MONITOR_4 ro — Monitor register 4. READ-ONLY.
  [16] PI_MONITOR_CAP_SEL_4 rw — Selection of captures for pi_monitor_4.
  [11:8] PI_MONITOR_SRC_SEL_4 rw — Selection of sources for pi_monitor_4.
  [7:0] PI_MONITOR_3 ro — Monitor register 3. READ-ONLY.
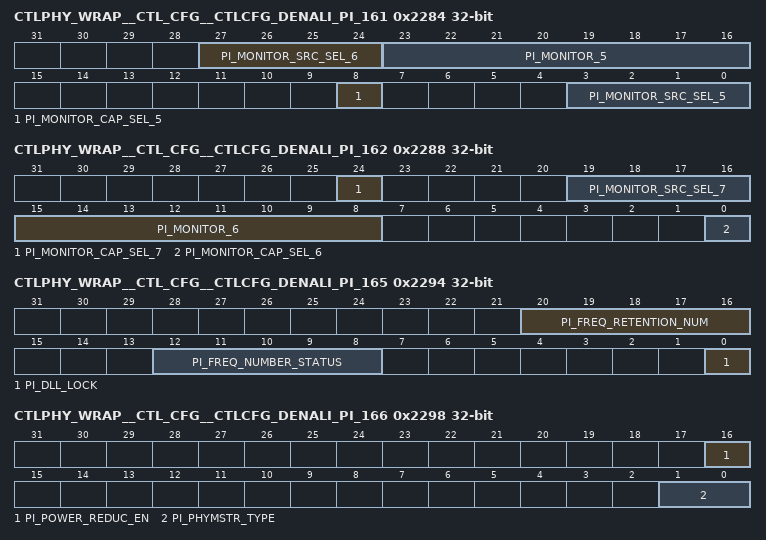
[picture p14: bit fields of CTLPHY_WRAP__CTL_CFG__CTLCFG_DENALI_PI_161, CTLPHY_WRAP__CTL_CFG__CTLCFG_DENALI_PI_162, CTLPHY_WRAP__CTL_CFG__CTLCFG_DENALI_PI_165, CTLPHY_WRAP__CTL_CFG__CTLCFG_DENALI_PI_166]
0x2284 CTLPHY_WRAP__CTL_CFG__CTLCFG_DENALI_PI_161 access per field
  [27:24] PI_MONITOR_SRC_SEL_6 rw — Selection of sources for pi_monitor_6.
  [23:16] PI_MONITOR_5 ro — Monitor register 5. READ-ONLY.
  [8] PI_MONITOR_CAP_SEL_5 rw — Selection of captures for pi_monitor_5.
  [3:0] PI_MONITOR_SRC_SEL_5 rw — Selection of sources for pi_monitor_5.
0x2288 CTLPHY_WRAP__CTL_CFG__CTLCFG_DENALI_PI_162 access per field
  [24] PI_MONITOR_CAP_SEL_7 rw — Selection of captures for pi_monitor_7.
  [19:16] PI_MONITOR_SRC_SEL_7 rw — Selection of sources for pi_monitor_7.
  [15:8] PI_MONITOR_6 ro — Monitor register 6. READ-ONLY.
  [0] PI_MONITOR_CAP_SEL_6 rw — Selection of captures for pi_monitor_6.
0x228C CTLPHY_WRAP__CTL_CFG__CTLCFG_DENALI_PI_163 ro
  [7:0] PI_MONITOR_7 — Monitor register 7. READ-ONLY.
0x2290 CTLPHY_WRAP__CTL_CFG__CTLCFG_DENALI_PI_164 wo
  [7:0] PI_MONITOR_STROBE — Strobe the pi_monitor once. Every bit corresponds respectively with a pi_monitor. WRITE-ONLY
0x2294 CTLPHY_WRAP__CTL_CFG__CTLCFG_DENALI_PI_165 access per field
  [20:16] PI_FREQ_RETENTION_NUM rw — Monitor active freq number in PI for data_retention
  [12:8] PI_FREQ_NUMBER_STATUS ro — Monitor active freq number in PI. READ-ONLY.
  [0] PI_DLL_LOCK ro — Monitor dfi_init_complete from PHY. READ-ONLY.
0x2298 CTLPHY_WRAP__CTL_CFG__CTLCFG_DENALI_PI_166
  [16] PI_POWER_REDUC_EN — PI Power reduction enable, 1 = enabled.
  [1:0] PI_PHYMSTR_TYPE — Defines how the controller should set the state of DRAM before turning control of the DFI bus over to the PI.
{0x2000+4i} CTLPHY_WRAP__CTL_CFG__CTLCFG_DENALI_PI_{i} access not given reset not defined (i=167..170)
0x22AC CTLPHY_WRAP__CTL_CFG__CTLCFG_DENALI_PI_171
  [23:16] PI_WRLVL_MAX_STROBE_PEND — Defines the maximum number of wrlvl_strobes that be accumulated before an AREF is prevented from being generated.
0x22B0 CTLPHY_WRAP__CTL_CFG__CTLCFG_DENALI_PI_172
  [8:0] PI_TREFBW_THR — Threshold value to control the AREF command interval. When the number of pending AREF is over this value, the interval is expanded to be tREF/8.
0x22B4 CTLPHY_WRAP__CTL_CFG__CTLCFG_DENALI_PI_173
  [4:0] PI_FREQ_CHANGE_REG_COPY — In non-DFI 4.0 mode, contains the frequency copy value.
0x22B8 CTLPHY_WRAP__CTL_CFG__CTLCFG_DENALI_PI_174
  [27:24] PI_CATR — It indicates LP4 DRAM CA terminition ON/OFF state. Each bit corresponds to each chip select. 1:ON 0:OFF. This parameter is active when PI_NO_CATR_READ==1. When PI_NO_CATR_READ==0, this param is inactive
  [16] PI_PARALLEL_CALVL_EN — Enable parallel channel CA training for LPDDR4. 1: All the channels in one rank do CA Training in parallel. 0: Each channel does CA Training in sequence
  [0] PI_FREQ_SEL_FROM_REGIF — In non-DFI 4.0 mode, user select the frequency copies from pi_freq_change_reg_copy.
0x22BC CTLPHY_WRAP__CTL_CFG__CTLCFG_DENALI_PI_175
  [24] PI_DISABLE_PHYMSTR_REQ — PI mask dfi_phymstr_req to the controller and get dfi bus without dfi_phymstr_ack, 1: disconnect
  [16] PI_DISCONNECT_MC — PI disconnects the controller from the PHY, 1: disconnect
  [8] PI_MASK_INIT_COMPLETE — Enable the masking of the dfi_init_complete signal back to the controller, 1: mask.
  [0] PI_NO_CATR_READ — Defines how the LPDDR4 termination status is determined. 1: PI use PI_CATR to get DRAM CA Termination status. 0: PI reads DRAM MR0.OP7 to get DRAM CA Termination status.
0x22C0 CTLPHY_WRAP__CTL_CFG__CTLCFG_DENALI_PI_176
  [31:16] PI_TVREF_F0 — Defines the number of cycles that the PI should wait before issuing the next command after a VREF training MRW command for frequency set 0.
  [10:8] PI_PHYMSTR_REQ_ACK_LOOP_DELAY — The delay between phymstr_req and inner phymstr_ack when PI_DISABLE_PHYMSTR_REQ set 1
  [0] PI_NOTCARE_MC_INIT_START — Defines whether PI waits for the controller to initiate dfi_init_start before PI memory initialization, 1: wait for dfi_init_start
0x22C4 CTLPHY_WRAP__CTL_CFG__CTLCFG_DENALI_PI_177
  [31:16] PI_TVREF_F2 — Defines the number of cycles that the PI should wait before issuing the next command after a VREF training MRW command for frequency set 2.
  [15:0] PI_TVREF_F1 — Defines the number of cycles that the PI should wait before issuing the next command after a VREF training MRW command for frequency set 1.
0x22C8 CTLPHY_WRAP__CTL_CFG__CTLCFG_DENALI_PI_178
  [23:16] PI_TSDO_F2 — The delay from the read preamble training MRS command to the data strobe drive out for frequency set 2, in PI clocks
  [15:8] PI_TSDO_F1 — The delay from the read preamble training MRS command to the data strobe drive out for frequency set 1, in PI clocks
  [7:0] PI_TSDO_F0 — The delay from the read preamble training MRS command to the data strobe drive out for frequency set 0, in PI clocks
0x22CC CTLPHY_WRAP__CTL_CFG__CTLCFG_DENALI_PI_179
  [7:0] PI_TDELAY_RDWR_2_BUS_IDLE_F0 — The delay from read or write to bus idle for frequency set 0. Recommend setting is: delay time from read command issued to last read data received.
0x22D0 CTLPHY_WRAP__CTL_CFG__CTLCFG_DENALI_PI_180
  [7:0] PI_TDELAY_RDWR_2_BUS_IDLE_F1 — The delay from read or write to bus idle for frequency set 1. Recommend setting is: delay time from read command issued to last read data received.
0x22D4 CTLPHY_WRAP__CTL_CFG__CTLCFG_DENALI_PI_181
  [19:8] PI_ZQINIT_F0 — Number of cycles needed for a ZQINIT command for frequency set 0.
  [7:0] PI_TDELAY_RDWR_2_BUS_IDLE_F2 — The delay from read or write to bus idle for frequency set 2. Recommend setting is: delay time from read command issued to last read data received.
0x22D8 CTLPHY_WRAP__CTL_CFG__CTLCFG_DENALI_PI_182
  [27:16] PI_ZQINIT_F2 — Number of cycles needed for a ZQINIT command for frequency set 2.
  [11:0] PI_ZQINIT_F1 — Number of cycles needed for a ZQINIT command for frequency set 1.
0x22DC CTLPHY_WRAP__CTL_CFG__CTLCFG_DENALI_PI_183
  [31:24] PI_TPARITY_ERROR_CMD_INHIBIT_F0 — Defines the window after the PI receives a parity error during which DRAM commands will not execute for frequency set 0.
  [19:16] PI_CA_PARITY_LAT_F0 — DRAM CA parity latency value in cycles for frequency set 0.
  [13:8] PI_ADDITIVE_LAT_F0 — DRAM additive latency value in cycles for frequency set 0.
  [6:0] PI_WRLAT_F0 — DRAM WRLAT value in cycles for frequency set 0.
0x22E0 CTLPHY_WRAP__CTL_CFG__CTLCFG_DENALI_PI_184
  [27:24] PI_CA_PARITY_LAT_F1 — DRAM CA parity latency value in cycles for frequency set 1.
  [21:16] PI_ADDITIVE_LAT_F1 — DRAM additive latency value in cycles for frequency set 1.
  [14:8] PI_WRLAT_F1 — DRAM WRLAT value in cycles for frequency set 1.
  [6:0] PI_CASLAT_LIN_F0 — Sets latency from read command sent to data received from/to controller for frequency set 0. Bit [0] is half-cycle increment and the upper bits define memory CAS latency for the controller.
0x22E4 CTLPHY_WRAP__CTL_CFG__CTLCFG_DENALI_PI_185
  [29:24] PI_ADDITIVE_LAT_F2 — DRAM additive latency value in cycles for frequency set 2.
  [22:16] PI_WRLAT_F2 — DRAM WRLAT value in cycles for frequency set 2.
  [14:8] PI_CASLAT_LIN_F1 — Sets latency from read command sent to data received from/to controller for frequency set 1. Bit [0] is half-cycle increment and the upper bits define memory CAS latency for the controller.
  [7:0] PI_TPARITY_ERROR_CMD_INHIBIT_F1 — Defines the window after the PI receives a parity error during which DRAM commands will not execute for frequency set 1.
0x22E8 CTLPHY_WRAP__CTL_CFG__CTLCFG_DENALI_PI_186
  [22:16] PI_CASLAT_LIN_F2 — Sets latency from read command sent to data received from/to controller for frequency set 2. Bit [0] is half-cycle increment and the upper bits define memory CAS latency for the controller.
  [15:8] PI_TPARITY_ERROR_CMD_INHIBIT_F2 — Defines the window after the PI receives a parity error during which DRAM commands will not execute for frequency set 2.
  [3:0] PI_CA_PARITY_LAT_F2 — DRAM CA parity latency value in cycles for frequency set 2.
0x22EC CTLPHY_WRAP__CTL_CFG__CTLCFG_DENALI_PI_187
  [9:0] PI_TRFC_F0 — DRAM tRFC value in memory clocks for frequency set 0.
0x22F0 CTLPHY_WRAP__CTL_CFG__CTLCFG_DENALI_PI_188
  [19:0] PI_TREF_F0 — DRAM tREF value in memory clocks for frequency set 0.
0x22F4 CTLPHY_WRAP__CTL_CFG__CTLCFG_DENALI_PI_189
  [9:0] PI_TRFC_F1 — DRAM tRFC value in memory clocks for frequency set 1.
0x22F8 CTLPHY_WRAP__CTL_CFG__CTLCFG_DENALI_PI_190
  [19:0] PI_TREF_F1 — DRAM tREF value in memory clocks for frequency set 1.
0x22FC CTLPHY_WRAP__CTL_CFG__CTLCFG_DENALI_PI_191
  [9:0] PI_TRFC_F2 — DRAM tRFC value in memory clocks for frequency set 2.
0x2300 CTLPHY_WRAP__CTL_CFG__CTLCFG_DENALI_PI_192 reset 0x2000000
  [27:24] PI_TDFI_CTRL_DELAY_F0 — Defines the DFI tCTRL_DELAY timing parameter [in DFI clocks] for frequency set 0, the delay between a DFI command change and a memory command.
  [19:0] PI_TREF_F2 — DRAM tREF value in memory clocks for frequency set 2.
